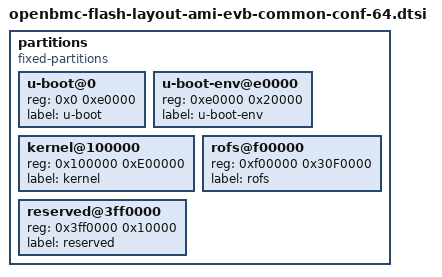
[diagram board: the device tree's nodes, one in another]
// SPDX-License-Identifier: GPL-2.0+
/*
 * Copyright (C) 2020 Bytedance.
 */

partitions {
	compatible = "fixed-partitions";
	#address-cells = <1>;
	#size-cells = <1>;

	u-boot@0 {
		reg = <0x0 0xe0000>; // 896KB
		label = "u-boot";
	};

	u-boot-env@e0000 {
		reg = <0xe0000 0x20000>; // 128KB
		label = "u-boot-env";
	};

	kernel@100000 {
		reg = <0x100000 0xE00000>; // 14MB
		label = "kernel";
	};

	rofs@f00000 {
		reg = <0xf00000 0x30F0000>; // 49MB
		label = "rofs";
	};

    reserved@3ff0000 {
        reg = <0x3ff0000 0x10000>; // 64kb
        label = "reserved";
    };
};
